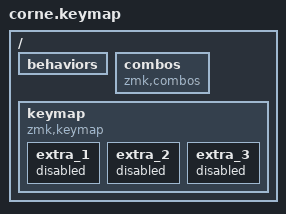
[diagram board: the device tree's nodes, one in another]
/*
 * Copyright (c) 2020 The ZMK Contributors
 *
 * SPDX-License-Identifier: MIT
 */

#include <behaviors.dtsi>
#include <dt-bindings/zmk/keys.h>
#include <dt-bindings/zmk/bt.h>

#include "helpers/french.dtsi"
// #include "helpers/macros.dtsi"
// #include "helpers/mouse.dtsi"

// Layers name
#define Base 0
#define Left 1
#define Right 2
#define Third 3
#define Mouse 4

/ {
    behaviors {
        #include "behaviors/hold_tap.dtsi"
    };

    combos {
        compatible = "zmk,combos";

        #include "combos/accents.dtsi"
        // #include "combos/mouse.dtsi"
    };

    // conditional_layers {
    //     // #include "conditional_layers/third_layer.dtsi"
    // };

    keymap {
        compatible = "zmk,keymap";
        #include "layers/default.dtsi"
        #include "layers/lower.dtsi"
        #include "layers/raise.dtsi"

        extra_1 {
            status = "reserved";
        };

        extra_2 {
            status = "reserved";
        };

        extra_3 {
            status = "reserved";
        };
    };
};
